AUTOSAR XML (schema 00050)
package /ComponentTypes
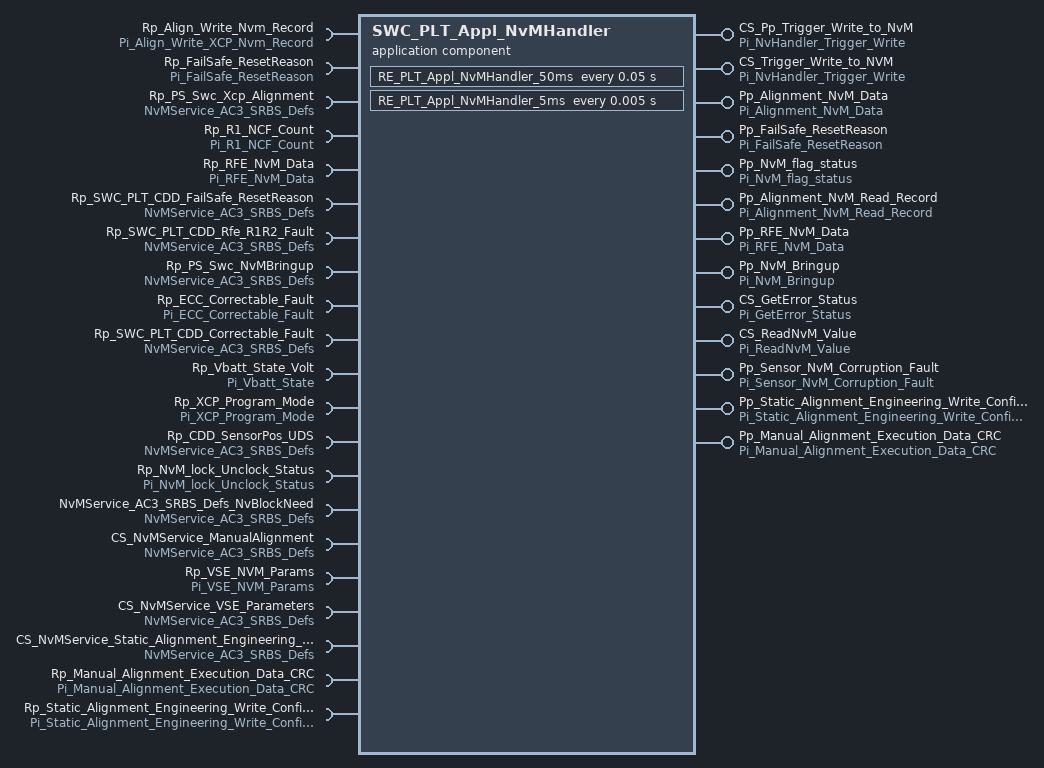
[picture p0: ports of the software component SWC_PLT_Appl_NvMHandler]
  application sw component type SWC_PLT_Appl_NvMHandler
    7 x provide port:
      CS_Pp_Trigger_Write_to_NvM: server-com-spec{operation=NvHandler_Trigger_Write_To_NVM, queue-length=1}, provided-interface=Pi_NvHandler_Trigger_Write
      CS_Trigger_Write_to_NVM: server-com-spec{operation=NvHandler_Trigger_Write_To_NVM, queue-length=1}, provided-interface=Pi_NvHandler_Trigger_Write
      Pp_Alignment_NvM_Data: nonqueued-sender-com-spec{data-element=Alignment_NvM_Data, init-value=constant-reference=C_Write_Alignment_NvM_Data}, provided-interface=Pi_Alignment_NvM_Data
      Pp_FailSafe_ResetReason: nonqueued-sender-com-spec{data-element=De_FailSafe_ResetReason, init-value=constant-reference=C_FailSafe_ResetReason_T}, provided-interface=Pi_FailSafe_ResetReason
      Pp_NvM_flag_status: nonqueued-sender-com-spec{data-element=Pim_write_status, init-value=0}, provided-interface=Pi_NvM_flag_status
      Pp_Alignment_NvM_Read_Record: nonqueued-sender-com-spec{data-element=De_Write_Alignment_NvM_Data, init-value=constant-reference=C_Write_Alignment_NvM_Data}, provided-interface=Pi_Alignment_NvM_Read_Record
      Pp_RFE_NvM_Data: nonqueued-sender-com-spec{data-element=De_RFE_NvM_Data, init-value=fields=[CORE_BANK_SFT_ERR_MON:0, CORE_BANK_SFT_ERR_STATUS:0, CORE_BANK_MCU_STS_MCU_MSSG:0, FUSA_IRQ0_FLAG_R:0, FUSA_IRQ1_FLAG_R:0, FUSA_IRQ2_FLAG_R:0, Api_ret_val:0, LOGEN_BANK_CHRP_GEN_ERROR:0, LOGEN_BANK_LOGEN_ERROR:0, CPU_SYS_MCU_ERR_0:0, CPU_SYS_MCU_ERR_1:0, CPU_SYS_MCU_ERR_2:0, CPU_SYS_MCU_ERR_3:0, ASYNC_BANK_ASYNC_ERR1:0, PROF_BANK_PRF_ERR1:0, PROF_BANK_PRF_ERR2:0, RXADC_FUSAMON:0, maf_status:0]}, provided-interface=Pi_RFE_NvM_Data
    7 x require port:
      Rp_Align_Write_Nvm_Record: nonqueued-receiver-com-spec{data-element=Alignment_Record, filter=data-filter-type=ALWAYS, init-value=constant-reference=C_Write_Alignment_NvM_Data}, required-interface=Pi_Align_Write_XCP_Nvm_Record
      Rp_FailSafe_ResetReason: nonqueued-receiver-com-spec{data-element=De_FailSafe_ResetReason, filter=data-filter-type=ALWAYS, init-value=constant-reference=C_FailSafe_ResetReason_T}, required-interface=Pi_FailSafe_ResetReason
      Rp_PS_Swc_Xcp_Alignment: required-com-specs=[EraseBlock, GetErrorStatus, InvalidateNvBlock, ReadBlock, RestoreBlockDefaults, SetRamBlockStatus, WriteBlock], required-interface=NvMService_AC3_SRBS_Defs
      Rp_R1_NCF_Count: nonqueued-receiver-com-spec{data-element=R1_NCF_Count, filter=data-filter-type=ALWAYS, init-value=0}, required-interface=Pi_R1_NCF_Count
      Rp_RFE_NvM_Data: nonqueued-receiver-com-spec{data-element=De_RFE_NvM_Data, filter=data-filter-type=ALWAYS, init-value=fields=[CORE_BANK_SFT_ERR_MON:0, CORE_BANK_SFT_ERR_STATUS:0, CORE_BANK_MCU_STS_MCU_MSSG:0, FUSA_IRQ0_FLAG_R:0, FUSA_IRQ1_FLAG_R:0, FUSA_IRQ2_FLAG_R:0, Api_ret_val:0, LOGEN_BANK_CHRP_GEN_ERROR:0, LOGEN_BANK_LOGEN_ERROR:0, CPU_SYS_MCU_ERR_0:0, CPU_SYS_MCU_ERR_1:0, CPU_SYS_MCU_ERR_2:0, CPU_SYS_MCU_ERR_3:0, ASYNC_BANK_ASYNC_ERR1:0, PROF_BANK_PRF_ERR1:0, PROF_BANK_PRF_ERR2:0, RXADC_FUSAMON:0, maf_status:0]}, required-interface=Pi_RFE_NvM_Data
      Rp_SWC_PLT_CDD_FailSafe_ResetReason: required-com-specs=[EraseBlock, GetErrorStatus, InvalidateNvBlock, ReadBlock, RestoreBlockDefaults, SetRamBlockStatus, WriteBlock], required-interface=NvMService_AC3_SRBS_Defs
      Rp_SWC_PLT_CDD_Rfe_R1R2_Fault: required-com-specs=[EraseBlock, GetErrorStatus, InvalidateNvBlock, ReadBlock, RestoreBlockDefaults, SetRamBlockStatus, WriteBlock], required-interface=NvMService_AC3_SRBS_Defs
    provide port Pp_NvM_Bringup: nonqueued-sender-com-spec=data-element=Bringup_NvM_Data, provided-interface=Pi_NvM_Bringup
    7 x require port:
      Rp_PS_Swc_NvMBringup: required-com-specs=[EraseBlock, InvalidateNvBlock, RestoreBlockDefaults, WriteBlock, ReadBlock, SetRamBlockStatus, GetErrorStatus], required-interface=NvMService_AC3_SRBS_Defs
      Rp_ECC_Correctable_Fault: nonqueued-receiver-com-spec{data-element=De_ECC_Correctable_Fault, filter=data-filter-type=ALWAYS, init-value=fields=[aa_mem_sec:0, artie_mem_sec:0, csi2_sec:0, dsp_opif_sec:0, dsp_idma_sec:0, dsp_iram_sec_axis:0, dsp_dcache_sec:0, dsp_dram_sec:0, dsp_icache_sec:0, dsp_iram_sec:0, ra_cqmem_sec:0, ra_dpmem_sec:0, ra_estmem_sec:0, ra_idxmem_sec:0, ra_phmem_sec:0, ra_wcmem_sec:0, sp_axi_m_corr:0, sp_axi_s_corr:0, sysmem0_sec:0, sysmem1_sec:0, not_recorded:0]}, required-interface=Pi_ECC_Correctable_Fault
      Rp_SWC_PLT_CDD_Correctable_Fault: required-com-specs=[EraseBlock, InvalidateNvBlock, RestoreBlockDefaults, WriteBlock, ReadBlock, SetRamBlockStatus, GetErrorStatus], required-interface=NvMService_AC3_SRBS_Defs
      Rp_Vbatt_State_Volt: nonqueued-receiver-com-spec{data-element=De_Vbatt_State, filter=data-filter-type=ALWAYS, init-value=0}, required-interface=Pi_Vbatt_State
      Rp_XCP_Program_Mode: nonqueued-receiver-com-spec{data-element=De_XCP_Program_Mode, filter=data-filter-type=ALWAYS, init-value=0}, required-interface=Pi_XCP_Program_Mode
      Rp_CDD_SensorPos_UDS: required-com-specs=[EraseBlock, InvalidateNvBlock, RestoreBlockDefaults, WriteBlock, ReadBlock, SetRamBlockStatus, GetErrorStatus], required-interface=NvMService_AC3_SRBS_Defs
      Rp_NvM_lock_Unclock_Status: nonqueued-receiver-com-spec{data-element=De_NvM_lock_Unclock_Status, filter=data-filter-type=ALWAYS, init-value=constant-reference=C_SensorPos_default}, required-interface=Pi_NvM_lock_Unclock_Status
    provide port CS_GetError_Status: server-com-spec{operation=Operation, queue-length=1}, provided-interface=Pi_GetError_Status
    provide port CS_ReadNvM_Value: server-com-spec{operation=Operation, queue-length=1}, provided-interface=Pi_ReadNvM_Value
    provide port Pp_Sensor_NvM_Corruption_Fault: nonqueued-sender-com-spec{data-element=De_Sensor_NvM_Corruption_Fault, init-value=170}, provided-interface=Pi_Sensor_NvM_Corruption_Fault
    5 x require port:
      NvMService_AC3_SRBS_Defs_NvBlockNeed: required-com-specs=[WriteBlock, SetRamBlockStatus, RestoreBlockDefaults, ReadBlock, InvalidateNvBlock, GetErrorStatus, EraseBlock], required-interface=NvMService_AC3_SRBS_Defs
      CS_NvMService_ManualAlignment: required-com-specs=[EraseBlock, InvalidateNvBlock, RestoreBlockDefaults, WriteBlock, ReadBlock, SetRamBlockStatus, GetErrorStatus], required-interface=NvMService_AC3_SRBS_Defs
      Rp_VSE_NVM_Params: nonqueued-receiver-com-spec{data-element=De_VSE_NVM_Params, filter=data-filter-type=ALWAYS, init-value=fields=[nvm_last_rem_swa_bias_deg:0, nvm_last_rem_speed_comp:0, nvm_last_rem_stop_yaw_bias_primary_radps:0, nvm_last_rem_stop_yaw_bias_secondary_radps:0, nvm_f_last_rem_swa_bias:0]}, required-interface=Pi_VSE_NVM_Params
      CS_NvMService_VSE_Parameters: required-com-specs=[EraseBlock, InvalidateNvBlock, RestoreBlockDefaults, WriteBlock, ReadBlock, SetRamBlockStatus, GetErrorStatus], required-interface=NvMService_AC3_SRBS_Defs
      CS_NvMService_Static_Alignment_Engineering_Write_Configuration_Parameters: required-com-specs=[EraseBlock, InvalidateNvBlock, RestoreBlockDefaults, WriteBlock, ReadBlock, SetRamBlockStatus, GetErrorStatus], required-interface=NvMService_AC3_SRBS_Defs
    provide port Pp_Static_Alignment_Engineering_Write_Configuration_Parameters_CRC: nonqueued-sender-com-spec{data-element=De_Static_Alignment_Engineering_Write_Configuration_Parameters_CRC, init-value=fields=[{short-label=Static_alignment_write_Params, fields=[AlignmentStatic_TargetAzimuth:0, AlignmentStatic_TargetElevation:0, AlignmentStatic_TargetDistance:0]}, Data_CRC:0]}, provided-interface=Pi_Static_Alignment_Engineering_Write_Configuration_Parameters_CRC
    provide port Pp_Manual_Alignment_Execution_Data_CRC: nonqueued-sender-com-spec{data-element=De_Manual_Alignment_Execution_Data_CRC, init-value=fields=[{short-label=Manual_Alignment_Execution_Data, fields=[AlignmentModeIn:0, 0, IntialMisalignmentAngleAzimuth:0, IntialMisalignmentAngleElevation:0]}, Data_CRC:0]}, provided-interface=Pi_Manual_Alignment_Execution_Data_CRC
    require port Rp_Manual_Alignment_Execution_Data_CRC: nonqueued-receiver-com-spec{data-element=De_Manual_Alignment_Execution_Data_CRC, filter=data-filter-type=ALWAYS, init-value=fields=[{short-label=Manual_Alignment_Execution_Data, fields=[AlignmentModeIn:0, 0, IntialMisalignmentAngleAzimuth:0, IntialMisalignmentAngleElevation:0]}, Data_CRC:0]}, required-interface=Pi_Manual_Alignment_Execution_Data_CRC
    require port Rp_Static_Alignment_Engineering_Write_Configuration_Parameters_CRC: nonqueued-receiver-com-spec{data-element=De_Static_Alignment_Engineering_Write_Configuration_Parameters_CRC, filter=data-filter-type=ALWAYS, init-value=fields=[{short-label=Static_alignment_write_Params, fields=[AlignmentStatic_TargetAzimuth:0, AlignmentStatic_TargetElevation:0, AlignmentStatic_TargetDistance:0]}, Data_CRC:0]}, required-interface=Pi_Static_Alignment_Engineering_Write_Configuration_Parameters_CRC
    behavior SWC_PLT_Appl_NvMHandler_InternalBehavior: handle-termination-and-restart=NO-SUPPORT
      ar-typed-per-instance-memorys:
        9 x data:
          Appl_Alignment_PIM: sw-calibration-access=READ-WRITE, type=Dt_Write_Alignment_NvM_Data_T, init-value=constant-reference=C_Write_Alignment_NvM_Data
          FailSafe_ResetReason_PIM: sw-calibration-access=READ-WRITE, type=Dt_FailSafe_ResetReason_T, init-value=constant-reference=C_FailSafe_ResetReason_T
          RFE_R1R2_PIM: sw-calibration-access=READ-WRITE, type=Dt_Rfe_REC_NREC_Fault, init-value=constant-reference=C_Rfe_R1R2_Fault_T
          NvMBringUp_PIM: sw-calibration-access=READ-ONLY, type=Dt_Write_Alignment_NvM_Data_T, init-value=constant-reference=C_Write_Alignment_NvM_Data
          Correctable_Fault_PIM: sw-calibration-access=READ-ONLY, type=Dt_ECC_Correctable_Error_Counters, init-value=constant-reference=C_ECC_Correctable_Error_Counters
          Sensorpos_PIM_UDS: sw-calibration-access=READ-ONLY, type=Dt_SensorPosition_Data_T, init-value=constant-reference=C_SensorPos_default
          Manual_Alignment_Execution_Data_PIM: sw-calibration-access=READ-ONLY, type=Dt_Manual_Alignment_Execution_Data_CRC, init-value=fields=[{short-label=Manual_Alignment_Execution_Data, fields=[AlignmentModeIn:0, 0, IntialMisalignmentAngleAzimuth:0, IntialMisalignmentAngleElevation:0]}, Data_CRC:0]
          VSE_NVM_Params_PIM: sw-calibration-access=READ-ONLY, type=Dt_VSE_NVM_Params, init-value=fields=[nvm_last_rem_swa_bias_deg:0, nvm_last_rem_speed_comp:0, nvm_last_rem_stop_yaw_bias_primary_radps:0, nvm_last_rem_stop_yaw_bias_secondary_radps:0, nvm_f_last_rem_swa_bias:0]
          Static_Alignment_Engineering_Write_Configuration_Parameters_PIM: sw-calibration-access=READ-ONLY, type=Dt_Static_Alignment_Engineering_Write_Configuration_Parameters_CRC, init-value=fields=[{short-label=Static_alignment_write_Params, fields=[AlignmentStatic_TargetAzimuth:0, AlignmentStatic_TargetElevation:0, AlignmentStatic_TargetDistance:0]}, Data_CRC:0]
      timing event TMT_SWC_PLT_Appl_NvMHandler_50ms: start-on-event=RE_PLT_Appl_NvMHandler_50ms, period=0.05
      init event SWC_PLT_Appl_NvMHandler_InitEvent: start-on-event=SWC_PLT_Appl_NvMHandler_Init
      4 x operation invoked event:
        OIT_CS_Pp_Trigger_Write_to_NvM_NvHandler_Trigger_Write_To_NVM_CS_Pp_Trigger_Write_to_NvM_NvHandler_Trigger_Write_To_NVM: start-on-event=Trigger_Write_to_NVM, operation=CS_Pp_Trigger_Write_to_NvM.NvHandler_Trigger_Write_To_NVM
        OIT_CS_Pp_Trigger_Write_to_NvM_NvHandler_Trigger_Write_To_NVM_CS_Trigger_Write_to_NVM_NvHandler_Trigger_Write_To_NVM: start-on-event=Trigger_Write_to_NVM, operation=CS_Trigger_Write_to_NVM.NvHandler_Trigger_Write_To_NVM
        OIT_CS_GetError_Status_Operation_CS_GetError_Status_Operation: start-on-event=CS_GetError_Status_Operation, operation=CS_GetError_Status.Operation
        OIT_CS_ReadNvM_Value_Operation_CS_ReadNvM_Value_Operation: start-on-event=CS_ReadNvM_Value_Operation, operation=CS_ReadNvM_Value.Operation
      timing event TMT_RE_PLT_Appl_NvMHandler_5ms: start-on-event=RE_PLT_Appl_NvMHandler_5ms, period=0.005
      port-api-options:
        enable-take-address=true, error-handling=NO-TRANSFORMER-ERROR-HANDLING, indirect-api=false, port=CS_Pp_Trigger_Write_to_NvM
        enable-take-address=false, error-handling=NO-TRANSFORMER-ERROR-HANDLING, indirect-api=false, port=CS_Trigger_Write_to_NVM
      6 x runnable:
        RE_PLT_Appl_NvMHandler_50ms
          data-receive-point-by-arguments:
            9 x access:
              REC_Rp_Align_Write_Nvm_Record_Alignment_Record: accessed-variable=Rp_Align_Write_Nvm_Record.Alignment_Record
              REC_Rp_R1_NCF_Count_R1_NCF_Count: accessed-variable=Rp_R1_NCF_Count.R1_NCF_Count
              REC_Rp_ECC_Correctable_Fault_De_ECC_Correctable_Fault: accessed-variable=Rp_ECC_Correctable_Fault.De_ECC_Correctable_Fault
              REC_Rp_Vbatt_State_Volt_De_Vbatt_State: accessed-variable=Rp_Vbatt_State_Volt.De_Vbatt_State
              REC_Rp_XCP_Program_Mode_De_XCP_Program_Mode: accessed-variable=Rp_XCP_Program_Mode.De_XCP_Program_Mode
              REC_Rp_NvM_lock_Unclock_Status_De_NvM_lock_Unclock_Status: accessed-variable=Rp_NvM_lock_Unclock_Status.De_NvM_lock_Unclock_Status
              REC_Rp_VSE_NVM_Params_De_VSE_NVM_Params: accessed-variable=Rp_VSE_NVM_Params.De_VSE_NVM_Params
              REC_Rp_Manual_Alignment_Execution_Data_CRC_De_Manual_Alignment_Execution_Data_CRC: accessed-variable=Rp_Manual_Alignment_Execution_Data_CRC.De_Manual_Alignment_Execution_Data_CRC
              REC_Rp_Static_Alignment_Engineering_Write_Configuration_Parameters_CRC_De_Static_Alignment_Engineering_Write_Configurati6C102BA0: accessed-variable=Rp_Static_Alignment_Engineering_Write_Configuration_Parameters_CRC.De_Static_Alignment_Engineering_Write_Configuration_Parameters_CRC
          data-send-points:
            4 x access:
              SEND_Pp_NvM_flag_status_Pim_write_status: accessed-variable=Pp_NvM_flag_status.Pim_write_status
              SEND_Pp_Read_NvM_record_De_Write_Alignment_NvM_Data: accessed-variable=Pp_Alignment_NvM_Read_Record.De_Write_Alignment_NvM_Data
              SEND_Pp_RFE_NvM_Data_De_RFE_NvM_Data: accessed-variable=Pp_RFE_NvM_Data.De_RFE_NvM_Data
              SEND_Pp_Sensor_NvM_Corruption_Fault_De_Sensor_NvM_Corruption_Fault: accessed-variable=Pp_Sensor_NvM_Corruption_Fault.De_Sensor_NvM_Corruption_Fault
          56 x sync call:
            SC_Rp_PS_Swc_Xcp_Alignment_EraseBlock: operation=Rp_PS_Swc_Xcp_Alignment.EraseBlock
            SC_Rp_PS_Swc_Xcp_Alignment_GetErrorStatus: operation=Rp_PS_Swc_Xcp_Alignment.GetErrorStatus
            SC_Rp_PS_Swc_Xcp_Alignment_ReadBlock: operation=Rp_PS_Swc_Xcp_Alignment.ReadBlock
            SC_Rp_PS_Swc_Xcp_Alignment_SetRamBlockStatus: operation=Rp_PS_Swc_Xcp_Alignment.SetRamBlockStatus
            SC_Rp_PS_Swc_Xcp_Alignment_WriteBlock: operation=Rp_PS_Swc_Xcp_Alignment.WriteBlock
            SC_Rp_SWC_PLT_CDD_FailSafe_ResetReason_GetErrorStatus: operation=Rp_SWC_PLT_CDD_FailSafe_ResetReason.GetErrorStatus
            SC_Rp_SWC_PLT_CDD_FailSafe_ResetReason_ReadBlock: operation=Rp_SWC_PLT_CDD_FailSafe_ResetReason.ReadBlock
            SC_Rp_SWC_PLT_CDD_FailSafe_ResetReason_WriteBlock: operation=Rp_SWC_PLT_CDD_FailSafe_ResetReason.WriteBlock
            SC_Rp_SWC_PLT_CDD_Rfe_R1R2_Fault_EraseBlock: operation=Rp_SWC_PLT_CDD_Rfe_R1R2_Fault.EraseBlock
            SC_Rp_SWC_PLT_CDD_Rfe_R1R2_Fault_GetErrorStatus: operation=Rp_SWC_PLT_CDD_Rfe_R1R2_Fault.GetErrorStatus
            SC_Rp_SWC_PLT_CDD_Rfe_R1R2_Fault_ReadBlock: operation=Rp_SWC_PLT_CDD_Rfe_R1R2_Fault.ReadBlock
            SC_Rp_SWC_PLT_CDD_Rfe_R1R2_Fault_RestoreBlockDefaults: operation=Rp_SWC_PLT_CDD_Rfe_R1R2_Fault.RestoreBlockDefaults
            SC_Rp_SWC_PLT_CDD_Rfe_R1R2_Fault_SetRamBlockStatus: operation=Rp_SWC_PLT_CDD_Rfe_R1R2_Fault.SetRamBlockStatus
            SC_Rp_SWC_PLT_CDD_Rfe_R1R2_Fault_WriteBlock: operation=Rp_SWC_PLT_CDD_Rfe_R1R2_Fault.WriteBlock
            SC_Rp_PS_Swc_NvMBringup_EraseBlock: operation=Rp_PS_Swc_NvMBringup.EraseBlock
            SC_Rp_PS_Swc_NvMBringup_GetErrorStatus: operation=Rp_PS_Swc_NvMBringup.GetErrorStatus
            SC_Rp_PS_Swc_NvMBringup_InvalidateNvBlock: operation=Rp_PS_Swc_NvMBringup.InvalidateNvBlock
            SC_Rp_PS_Swc_NvMBringup_ReadBlock: operation=Rp_PS_Swc_NvMBringup.ReadBlock
            SC_Rp_PS_Swc_NvMBringup_RestoreBlockDefaults: operation=Rp_PS_Swc_NvMBringup.RestoreBlockDefaults
            SC_Rp_PS_Swc_NvMBringup_SetRamBlockStatus: operation=Rp_PS_Swc_NvMBringup.SetRamBlockStatus
            SC_Rp_PS_Swc_NvMBringup_WriteBlock: operation=Rp_PS_Swc_NvMBringup.WriteBlock
            SC_Rp_SWC_PLT_CDD_Correctable_Fault_EraseBlock: operation=Rp_SWC_PLT_CDD_Correctable_Fault.EraseBlock
            SC_Rp_SWC_PLT_CDD_Correctable_Fault_GetErrorStatus: operation=Rp_SWC_PLT_CDD_Correctable_Fault.GetErrorStatus
            SC_Rp_SWC_PLT_CDD_Correctable_Fault_InvalidateNvBlock: operation=Rp_SWC_PLT_CDD_Correctable_Fault.InvalidateNvBlock
            SC_Rp_SWC_PLT_CDD_Correctable_Fault_ReadBlock: operation=Rp_SWC_PLT_CDD_Correctable_Fault.ReadBlock
            SC_Rp_SWC_PLT_CDD_Correctable_Fault_RestoreBlockDefaults: operation=Rp_SWC_PLT_CDD_Correctable_Fault.RestoreBlockDefaults
            SC_Rp_SWC_PLT_CDD_Correctable_Fault_SetRamBlockStatus: operation=Rp_SWC_PLT_CDD_Correctable_Fault.SetRamBlockStatus
            SC_Rp_SWC_PLT_CDD_Correctable_Fault_WriteBlock: operation=Rp_SWC_PLT_CDD_Correctable_Fault.WriteBlock
            SC_Rp_CDD_SensorPos_UDS_EraseBlock: operation=Rp_CDD_SensorPos_UDS.EraseBlock
            SC_Rp_CDD_SensorPos_UDS_GetErrorStatus: operation=Rp_CDD_SensorPos_UDS.GetErrorStatus
            SC_Rp_CDD_SensorPos_UDS_InvalidateNvBlock: operation=Rp_CDD_SensorPos_UDS.InvalidateNvBlock
            SC_Rp_CDD_SensorPos_UDS_ReadBlock: operation=Rp_CDD_SensorPos_UDS.ReadBlock
            SC_Rp_CDD_SensorPos_UDS_RestoreBlockDefaults: operation=Rp_CDD_SensorPos_UDS.RestoreBlockDefaults
            SC_Rp_CDD_SensorPos_UDS_SetRamBlockStatus: operation=Rp_CDD_SensorPos_UDS.SetRamBlockStatus
            SC_Rp_CDD_SensorPos_UDS_WriteBlock: operation=Rp_CDD_SensorPos_UDS.WriteBlock
            SC_CS_NvMService_ManualAlignment_EraseBlock: operation=CS_NvMService_ManualAlignment.EraseBlock
            SC_CS_NvMService_ManualAlignment_GetErrorStatus: operation=CS_NvMService_ManualAlignment.GetErrorStatus
            SC_CS_NvMService_ManualAlignment_InvalidateNvBlock: operation=CS_NvMService_ManualAlignment.InvalidateNvBlock
            SC_CS_NvMService_ManualAlignment_ReadBlock: operation=CS_NvMService_ManualAlignment.ReadBlock
            SC_CS_NvMService_ManualAlignment_RestoreBlockDefaults: operation=CS_NvMService_ManualAlignment.RestoreBlockDefaults
            SC_CS_NvMService_ManualAlignment_SetRamBlockStatus: operation=CS_NvMService_ManualAlignment.SetRamBlockStatus
            SC_CS_NvMService_ManualAlignment_WriteBlock: operation=CS_NvMService_ManualAlignment.WriteBlock
            SC_CS_NvMService_VSE_Parameters_EraseBlock: operation=CS_NvMService_VSE_Parameters.EraseBlock
            SC_CS_NvMService_VSE_Parameters_GetErrorStatus: operation=CS_NvMService_VSE_Parameters.GetErrorStatus
            SC_CS_NvMService_VSE_Parameters_InvalidateNvBlock: operation=CS_NvMService_VSE_Parameters.InvalidateNvBlock
            SC_CS_NvMService_VSE_Parameters_ReadBlock: operation=CS_NvMService_VSE_Parameters.ReadBlock
            SC_CS_NvMService_VSE_Parameters_RestoreBlockDefaults: operation=CS_NvMService_VSE_Parameters.RestoreBlockDefaults
            SC_CS_NvMService_VSE_Parameters_SetRamBlockStatus: operation=CS_NvMService_VSE_Parameters.SetRamBlockStatus
            SC_CS_NvMService_VSE_Parameters_WriteBlock: operation=CS_NvMService_VSE_Parameters.WriteBlock
            SC_CS_NvMService_Static_Alignment_Engineering_Write_Configuration_Parameters_EraseBlock: operation=CS_NvMService_Static_Alignment_Engineering_Write_Configuration_Parameters.EraseBlock
            SC_CS_NvMService_Static_Alignment_Engineering_Write_Configuration_Parameters_GetErrorStatus: operation=CS_NvMService_Static_Alignment_Engineering_Write_Configuration_Parameters.GetErrorStatus
            SC_CS_NvMService_Static_Alignment_Engineering_Write_Configuration_Parameters_InvalidateNvBlock: operation=CS_NvMService_Static_Alignment_Engineering_Write_Configuration_Parameters.InvalidateNvBlock
            SC_CS_NvMService_Static_Alignment_Engineering_Write_Configuration_Parameters_ReadBlock: operation=CS_NvMService_Static_Alignment_Engineering_Write_Configuration_Parameters.ReadBlock
            SC_CS_NvMService_Static_Alignment_Engineering_Write_Configuration_Parameters_RestoreBlockDefaults: operation=CS_NvMService_Static_Alignment_Engineering_Write_Configuration_Parameters.RestoreBlockDefaults
            SC_CS_NvMService_Static_Alignment_Engineering_Write_Configuration_Parameters_SetRamBlockStatus: operation=CS_NvMService_Static_Alignment_Engineering_Write_Configuration_Parameters.SetRamBlockStatus
            SC_CS_NvMService_Static_Alignment_Engineering_Write_Configuration_Parameters_WriteBlock: operation=CS_NvMService_Static_Alignment_Engineering_Write_Configuration_Parameters.WriteBlock
        SWC_PLT_Appl_NvMHandler_Init
          data-receive-point-by-arguments:
            access REC_Rp_FailSafe_ResetReason_De_FailSafe_ResetReason: accessed-variable=Rp_FailSafe_ResetReason.De_FailSafe_ResetReason
          data-send-points:
            5 x access:
              SEND_Pp_Alignment_NvM_Data_Alignment_NvM_Data: accessed-variable=Pp_Alignment_NvM_Data.Alignment_NvM_Data
              SEND_Pp_FailSafe_ResetReason_De_FailSafe_ResetReason: accessed-variable=Pp_FailSafe_ResetReason.De_FailSafe_ResetReason
              SEND_Pp_RFE_NvM_Data_De_RFE_NvM_Data: accessed-variable=Pp_RFE_NvM_Data.De_RFE_NvM_Data
              SEND_Pp_Manual_Alignment_Execution_Data_CRC_De_Manual_Alignment_Execution_Data_CRC: accessed-variable=Pp_Manual_Alignment_Execution_Data_CRC.De_Manual_Alignment_Execution_Data_CRC
              SEND_Pp_Static_Alignment_Engineering_Write_Configuration_Parameters_CRC_De_Static_Alignment_Engineering_Write_Configurat6D9EDFB8: accessed-variable=Pp_Static_Alignment_Engineering_Write_Configuration_Parameters_CRC.De_Static_Alignment_Engineering_Write_Configuration_Parameters_CRC
          sync call SC_Rp_SWC_PLT_CDD_FailSafe_ResetReason_GetErrorStatus: operation=Rp_SWC_PLT_CDD_FailSafe_ResetReason.GetErrorStatus
          sync call SC_Rp_SWC_PLT_CDD_FailSafe_ResetReason_ReadBlock: operation=Rp_SWC_PLT_CDD_FailSafe_ResetReason.ReadBlock
          sync call SC_Rp_SWC_PLT_CDD_FailSafe_ResetReason_WriteBlock: operation=Rp_SWC_PLT_CDD_FailSafe_ResetReason.WriteBlock
        Trigger_Write_to_NVM: can-be-invoked-concurrently=true
          data-receive-point-by-arguments:
            access REC_Pi_RFE_NvM_Data_De_RFE_NvM_Data: accessed-variable=Rp_RFE_NvM_Data.De_RFE_NvM_Data
          sync call SC_Rp_SWC_PLT_CDD_FailSafe_ResetReason_GetErrorStatus: operation=Rp_SWC_PLT_CDD_FailSafe_ResetReason.GetErrorStatus
          sync call SC_Rp_SWC_PLT_CDD_FailSafe_ResetReason_ReadBlock: operation=Rp_SWC_PLT_CDD_FailSafe_ResetReason.ReadBlock
          sync call SC_Rp_SWC_PLT_CDD_FailSafe_ResetReason_WriteBlock: operation=Rp_SWC_PLT_CDD_FailSafe_ResetReason.WriteBlock
        CS_GetError_Status_Operation
        CS_ReadNvM_Value_Operation: can-be-invoked-concurrently=true
        RE_PLT_Appl_NvMHandler_5ms
      9 x swc service dependency, all with category=SERVICE:
        Alignment_NvMBlock: assigned-datas=role-based-data-assignment={role=defaultValue, used-parameter-element=Alignment_NvMBlock_DefaultValue}, assigned-ports=role-based-port-assignment={port-prototype=Rp_PS_Swc_Xcp_Alignment, role=NvMService_AC3_SRBS_Defs}
          service-needs:
            nv block needs Alignment_NvMBlock: n-data-sets=0, ram-block-status-control=API, reliability=ERROR-DETECTION, restore-at-start=true, store-at-shutdown=true, writing-priority=LOW
        SWC_PLT_CDD_FailSafe: assigned-ports=role-based-port-assignment={port-prototype=Rp_SWC_PLT_CDD_FailSafe_ResetReason, role=NvMService_AC3_SRBS_Defs}
          assigned-datas:
            role=defaultValue, used-parameter-element=SWC_PLT_CDD_FailSafe_DefaultValue
            role=ramBlock, used-data-element=FailSafe_ResetReason_PIM
          service-needs:
            nv block needs SWC_PLT_CDD_FailSafe: n-data-sets=0, ram-block-status-control=API, reliability=ERROR-DETECTION, restore-at-start=true, store-at-shutdown=true, writing-priority=LOW
        RFE_R1R2_Fault_NvM: assigned-ports=role-based-port-assignment={port-prototype=Rp_SWC_PLT_CDD_Rfe_R1R2_Fault, role=NvMService_AC3_SRBS_Defs}
          assigned-datas:
            role=defaultValue, used-parameter-element=RFE_R1R2_Fault_NvM_DefaultValue
            role=ramBlock, used-data-element=RFE_R1R2_PIM
          service-needs:
            nv block needs RFE_R1R2_Fault_NvM: n-data-sets=0, ram-block-status-control=API, reliability=NO-PROTECTION, restore-at-start=true, store-at-shutdown=true, writing-priority=LOW
        Bringup_NvMBlock: assigned-ports=role-based-port-assignment={port-prototype=Rp_PS_Swc_NvMBringup, role=NvMService_AC3_SRBS_Defs}
          assigned-datas:
            role=defaultValue, used-parameter-element=NvMBringUp_DefaultValue
            role=ramBlock, used-data-element=NvMBringUp_PIM
          service-needs:
            nv block needs Bringup_NvMBlock: n-data-sets=0, ram-block-status-control=API, reliability=ERROR-DETECTION, restore-at-start=true, store-at-shutdown=true, writing-priority=LOW
        Correctable_Fault_NvM: assigned-ports=role-based-port-assignment={port-prototype=Rp_SWC_PLT_CDD_Correctable_Fault, role=NvMService_AC3_SRBS_Defs}
          assigned-datas:
            role=defaultValue, used-parameter-element=Correctable_Fault_NvM_DefaultValue
            role=ramBlock, used-data-element=Correctable_Fault_PIM
          service-needs:
            nv block needs Correctable_Fault_NvM: n-rom-blocks=1, ram-block-status-control=API, reliability=ERROR-CORRECTION, restore-at-start=true, store-at-shutdown=true, writing-priority=LOW
        SensorPos_NvM: assigned-ports=role-based-port-assignment={port-prototype=Rp_CDD_SensorPos_UDS, role=NvMService_AC3_SRBS_Defs}
          assigned-datas:
            role=defaultValue, used-parameter-element=SensorPos_NvM_DefaultValue
            role=ramBlock, used-data-element=Sensorpos_PIM_UDS
          service-needs:
            nv block needs SensorPos_NvM: n-rom-blocks=1, ram-block-status-control=API, reliability=ERROR-CORRECTION, restore-at-start=true, store-at-shutdown=true, writing-priority=LOW
        SWC_Manual_alignment_Execution: assigned-ports=role-based-port-assignment={port-prototype=CS_NvMService_ManualAlignment, role=NvMService_AC3_SRBS_Defs}
          assigned-datas:
            role=defaultValue, used-parameter-element=SWC_Manual_alignment_Execution_DefaultValue
            role=ramBlock, used-data-element=Manual_Alignment_Execution_Data_PIM
          service-needs:
            nv block needs SWC_Manual_alignment_Execution: n-rom-blocks=1, ram-block-status-control=API, reliability=ERROR-CORRECTION, restore-at-start=true, store-at-shutdown=true, writing-priority=LOW
        SWC_VSE_NVM_Params: assigned-ports=role-based-port-assignment={port-prototype=CS_NvMService_VSE_Parameters, role=NvMService_AC3_SRBS_Defs}
          assigned-datas:
            role=defaultValue, used-parameter-element=SWC_VSE_NVM_Params_DefaultValue
            role=ramBlock, used-data-element=VSE_NVM_Params_PIM
          service-needs:
            nv block needs SWC_VSE_NVM_Params: n-data-sets=0, ram-block-status-control=API, reliability=ERROR-CORRECTION, restore-at-start=true, store-at-shutdown=true, writing-priority=LOW
        SWC_Static_Alignment_Write_Parameters: assigned-ports=role-based-port-assignment={port-prototype=CS_NvMService_Static_Alignment_Engineering_Write_Configuration_Parameters, role=NvMService_AC3_SRBS_Defs}
          assigned-datas:
            role=defaultValue, used-parameter-element=SWC_Static_Alignment_Write_Parameters_DefaultValue
            role=ramBlock, used-data-element=Static_Alignment_Engineering_Write_Configuration_Parameters_PIM
          service-needs:
            nv block needs SWC_Static_Alignment_Write_Parameters: n-rom-blocks=1, ram-block-status-control=API, reliability=ERROR-CORRECTION, restore-at-start=true, store-at-shutdown=true
      shared-parameters:
        9 x parameter data prototype, all with sw-calibration-access=READ-WRITE:
          Alignment_NvMBlock_DefaultValue: type=Dt_Write_Alignment_NvM_Data_T
          RFE_R1R2_Fault_NvM_DefaultValue: type=Dt_Rfe_REC_NREC_Fault
          SWC_PLT_CDD_FailSafe_DefaultValue: type=Dt_FailSafe_ResetReason_T
          NvMBringUp_DefaultValue: type=Dt_Write_Alignment_NvM_Data_T
          Correctable_Fault_NvM_DefaultValue: type=Dt_ECC_Correctable_Error_Counters, init-value=constant-reference=C_ECC_Correctable_Error_Counters
          SensorPos_NvM_DefaultValue: type=Dt_SensorPosition_Data_T, init-value=constant-reference=C_SensorPos_default
          SWC_Manual_alignment_Execution_DefaultValue: type=Dt_Manual_Alignment_Execution_Data_CRC, init-value=fields=[{short-label=Manual_Alignment_Execution_Data, fields=[AlignmentModeIn:0, 0, IntialMisalignmentAngleAzimuth:0, IntialMisalignmentAngleElevation:0]}, Data_CRC:0]
          SWC_VSE_NVM_Params_DefaultValue: type=Dt_VSE_NVM_Params, init-value=fields=[nvm_last_rem_swa_bias_deg:0, nvm_last_rem_speed_comp:0, nvm_last_rem_stop_yaw_bias_primary_radps:0, nvm_last_rem_stop_yaw_bias_secondary_radps:0, nvm_f_last_rem_swa_bias:0]
          SWC_Static_Alignment_Write_Parameters_DefaultValue: type=Dt_Static_Alignment_Engineering_Write_Configuration_Parameters_CRC, init-value=fields=[{short-label=Static_alignment_write_Params, fields=[AlignmentStatic_TargetAzimuth:0, AlignmentStatic_TargetElevation:0, AlignmentStatic_TargetDistance:0]}, Data_CRC:0]
  swc implementation SWC_PLT_Appl_NvMHandler_Implementation: behavior=SWC_PLT_Appl_NvMHandler_InternalBehavior
    code-descriptors:
      code Default: artifact-descriptors=autosar-engineering-object=category=SWSRC
